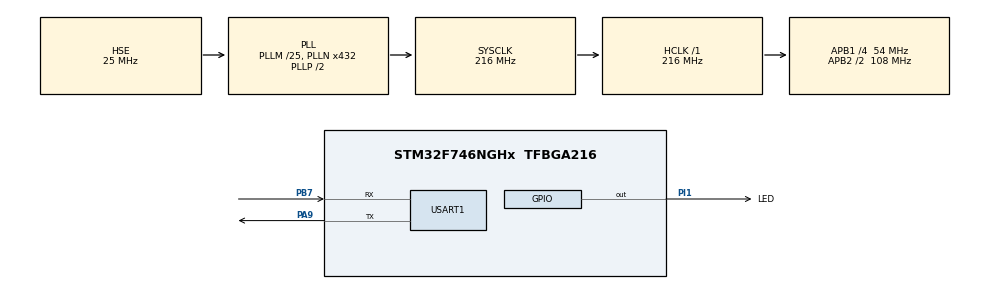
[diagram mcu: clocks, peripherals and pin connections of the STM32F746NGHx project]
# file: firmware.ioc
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FREERTOS.INCLUDE_vTaskDelayUntil=1
FREERTOS.Tasks01=defaultTask,0,128,StartDefaultTask,Default,NULL,Dynamic,NULL,NULL
FREERTOS.configTICK_RATE_HZ=1000
Mcu.Family=STM32F7
Mcu.Name=STM32F746NGHx
Mcu.Package=TFBGA216
NVIC.PriorityGroup=NVIC_PRIORITYGROUP_4
NVIC.TIM6_DAC_IRQn=true\:15\:0\:false\:false\:true\:false\:false\:true\:true
NVIC.TimeBase=TIM6_DAC_IRQn
NVIC.TimeBaseIP=TIM6
PA13.Mode=Serial_Wire
PA13.Signal=SYS_JTMS-SWDIO
PA14.Mode=Serial_Wire
PA14.Signal=SYS_JTCK-SWCLK
PA9.Mode=Asynchronous
PA9.Signal=USART1_TX
PB7.Mode=Asynchronous
PB7.Signal=USART1_RX
PH0/OSC_IN.Mode=HSE-External-Oscillator
PH0/OSC_IN.Signal=RCC_OSC_IN
PH1/OSC_OUT.Mode=HSE-External-Oscillator
PH1/OSC_OUT.Signal=RCC_OSC_OUT
PI1.GPIO_Label=LED
PI1.Signal=GPIO_Output
ProjectManager.HeapSize=0x200
ProjectManager.StackSize=0x400
ProjectManager.TargetToolchain=Makefile
RCC.AHBFreq_Value=216000000
RCC.APB1CLKDivider=RCC_HCLK_DIV4
RCC.APB1Freq_Value=54000000
RCC.APB1TimFreq_Value=108000000
RCC.APB2CLKDivider=RCC_HCLK_DIV2
RCC.APB2Freq_Value=108000000
RCC.APB2TimFreq_Value=216000000
RCC.CortexFreq_Value=216000000
RCC.HCLKFreq_Value=216000000
RCC.HSE_VALUE=25000000
RCC.HSI_VALUE=16000000
RCC.LSE_VALUE=32768
RCC.PLLM=25
RCC.PLLN=432
RCC.PLLSourceVirtual=RCC_PLLSOURCE_HSE
RCC.SYSCLKFreq_VALUE=216000000
RCC.SYSCLKSource=RCC_SYSCLKSOURCE_PLLCLK
RCC.USBFreq_Value=216000000
RCC.VCOOutputFreq_Value=432000000
USART1.VirtualMode-Asynchronous=VM_ASYNC
VP_FREERTOS_VS_CMSIS_V1.Mode=CMSIS_V1
VP_SYS_VS_tim6.Mode=TIM6
board=STM32F746G-DISCO

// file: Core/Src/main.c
/* USER CODE BEGIN Header */
/**
  ******************************************************************************
  * @file           : main.c
  * @brief          : Main program body
  ******************************************************************************
  * @attention
  *
  * Copyright (c) 2023 STMicroelectronics.
  * All rights reserved.
  *
  * This software is licensed under terms that can be found in the LICENSE file
  * in the root directory of this software component.
  * If no LICENSE file comes with this software, it is provided AS-IS.
  *
  ******************************************************************************
  */
/* USER CODE END Header */
#include "main.h"
#include "cmsis_os.h"
#include "usart.h"
#include "gpio.h"

/* USER CODE BEGIN Includes */
#include "FreeRTOS.h"
#include "task.h"
#include "semphr.h"
#include <stdio.h>
#include <string.h>
/* USER CODE END Includes */

/* USER CODE BEGIN PD */
#define STACK_SIZE 1000
#define Delay 100

#define QUEUE_LENGTH 1
#define QUEUE_ITEM_SIZE sizeof(uint16_t)
/* USER CODE END PD */

/* USER CODE BEGIN PV */
/* Semaphore */
SemaphoreHandle_t Semaphore;

/* Handle */
TaskHandle_t xHandlegive = NULL;
TaskHandle_t xHandletake = NULL;

/* Queue */
QueueHandle_t q_time = NULL;

/* USER CODE END PV */

void SystemClock_Config(void);
void MX_FREERTOS_Init(void);
/* USER CODE BEGIN PFP */
void LedBlinker (void * pvParameters);

void taskGive(void *pvParameters);
void taskTake(void *unsued);
/* USER CODE END PFP */

/* USER CODE BEGIN 0 */

/* Fonction Give*/
void taskGive(void *pvParameters) {

    int delay = (int) pvParameters;
    uint8_t uartTxBuffer[100];
    char* s = pcTaskGetName(xTaskGetCurrentTaskHandle());

    //Fixation de la fréquence du sémaphore
    TickType_t xLastWakeTime;
    xLastWakeTime =  xTaskGetTickCount();
    const TickType_t xFrequency = delay;

    for(;;)
    {

      //Délais avec précision
      vTaskDelayUntil(&xLastWakeTime,xFrequency);

      // Affichage sur console
      sprintf((char*)uartTxBuffer, "Je suis la tache %s avant de donner la notification\n", s);
      HAL_UART_Transmit(&huart1, uartTxBuffer, strlen((char*)uartTxBuffer), HAL_MAX_DELAY);

      //Envoi de la valeur du Timer dans la queue
      xQueueSend(q_time,(void*) &delay,portMAX_DELAY);

      //Envoi de la notification à la tache take
      xTaskNotifyGive(xHandletake);

      //Verification avec la LED
      HAL_GPIO_WritePin(LED_GPIO_Port,LED_Pin,GPIO_PIN_RESET);

      sprintf((char*)uartTxBuffer, "Je suis la tache %s apres avoir donner la notification tous les %d ms\n", s, delay);
      HAL_UART_Transmit(&huart1, uartTxBuffer, strlen((char*)uartTxBuffer), HAL_MAX_DELAY);

      /* Attente de la prise de notification */
      ulTaskNotifyTake( pdTRUE, portMAX_DELAY );

    }

}

/* Focntion Take*/
void taskTake(void *unsued) {

    uint8_t uartTxBuffer[100];
    uint8_t timer;

    for(;;)
    {
        /* Attente de la prise de notification */
        ulTaskNotifyTake( pdTRUE, portMAX_DELAY );

        //Verification avec la LED
        HAL_GPIO_WritePin(LED_GPIO_Port,LED_Pin,GPIO_PIN_SET);

        /* Reception d'élément de la queue*/
        xQueueReceive(q_time,(void*)&timer,portMAX_DELAY);

        sprintf((char*)uartTxBuffer,"La valeur du Timer de la tache Give est %d\n", timer);
        HAL_UART_Transmit(&huart1, uartTxBuffer, strlen((char*)uartTxBuffer), HAL_MAX_DELAY);

        //Envoi de la notification à la tache Give
        xTaskNotifyGive(xHandlegive);

  }
}

/* USER CODE END 0 */

int main(void)
{

  /* MCU Configuration--------------------------------------------------------*/

  /* Reset of all peripherals, Initializes the Flash interface and the Systick. */
  HAL_Init();

  /* Configure the system clock */
  SystemClock_Config();

  /* Initialize all configured peripherals */
  MX_GPIO_Init();
  MX_USART1_UART_Init();
  /* USER CODE BEGIN 2 */

  /* Create a taskGive*/
  xTaskCreate(
          taskGive,       // Function to be called
          "Give",         // Name of task
          STACK_SIZE,     // Stack size
          (void*) Delay,  // Parameter to pass to function
          1,              // Task priority 0 to configMAX_PRIORITIES - 1 (FreeRTOSConfig.h)
          &xHandlegive       // Task handle (allows to find and manipulate the task)
          );

  /* Create a taskTake*/
  xTaskCreate(
          taskTake,       // Function to be called
          "Take",         // Name of task
          STACK_SIZE,     // Stack size
          NULL,           // Parameter to pass to function
          2,              // Task priority 0 to configMAX_PRIORITIES - 1 (FreeRTOSConfig.h)
          &xHandletake       // Task handle (allows to find and manipulate the task)
          );

  /* Create a queue*/
  q_time = xQueueCreate(QUEUE_LENGTH,QUEUE_ITEM_SIZE);

  /* USER CODE END 2 */

  /* Call init function for freertos objects (in freertos.c) */
  MX_FREERTOS_Init();

  /* Start scheduler */
  osKernelStart();
  /* We should never get here as control is now taken by the scheduler */
  /* Infinite loop */
  /* USER CODE BEGIN WHILE */
  /* Redirect stdout to UART */

  while (1)
  {
    // HAL_Delay(1000);
    // HAL_GPIO_TogglePin(LED_GPIO_Port,LED_Pin);
    /* USER CODE END WHILE */

  }
}

void SystemClock_Config(void)
{
  RCC_OscInitTypeDef RCC_OscInitStruct = {0};
  RCC_ClkInitTypeDef RCC_ClkInitStruct = {0};

  /** Configure the main internal regulator output voltage
  */
  __HAL_RCC_PWR_CLK_ENABLE();
  __HAL_PWR_VOLTAGESCALING_CONFIG(PWR_REGULATOR_VOLTAGE_SCALE1);

  /** Initializes the RCC Oscillators according to the specified parameters
  * in the RCC_OscInitTypeDef structure.
  */
  RCC_OscInitStruct.OscillatorType = RCC_OSCILLATORTYPE_HSE;
  RCC_OscInitStruct.HSEState = RCC_HSE_ON;
  RCC_OscInitStruct.PLL.PLLState = RCC_PLL_ON;
  RCC_OscInitStruct.PLL.PLLSource = RCC_PLLSOURCE_HSE;
  RCC_OscInitStruct.PLL.PLLM = 25;
  RCC_OscInitStruct.PLL.PLLN = 432;
  RCC_OscInitStruct.PLL.PLLP = RCC_PLLP_DIV2;
  RCC_OscInitStruct.PLL.PLLQ = 2;
  if (HAL_RCC_OscConfig(&RCC_OscInitStruct) != HAL_OK)
  {
    Error_Handler();
  }

  /** Activate the Over-Drive mode
  */
  if (HAL_PWREx_EnableOverDrive() != HAL_OK)
  {
    Error_Handler();
  }

  /** Initializes the CPU, AHB and APB buses clocks
  */
  RCC_ClkInitStruct.ClockType = RCC_CLOCKTYPE_HCLK|RCC_CLOCKTYPE_SYSCLK
                              |RCC_CLOCKTYPE_PCLK1|RCC_CLOCKTYPE_PCLK2;
  RCC_ClkInitStruct.SYSCLKSource = RCC_SYSCLKSOURCE_PLLCLK;
  RCC_ClkInitStruct.AHBCLKDivider = RCC_SYSCLK_DIV1;
  RCC_ClkInitStruct.APB1CLKDivider = RCC_HCLK_DIV4;
  RCC_ClkInitStruct.APB2CLKDivider = RCC_HCLK_DIV2;

  if (HAL_RCC_ClockConfig(&RCC_ClkInitStruct, FLASH_LATENCY_7) != HAL_OK)
  {
    Error_Handler();
  }
}

void HAL_TIM_PeriodElapsedCallback(TIM_HandleTypeDef *htim)
{
  if (htim->Instance == TIM6) {
    HAL_IncTick();
  }
}

void Error_Handler(void)
{
  __disable_irq();
  while (1)
  {
  }
}
